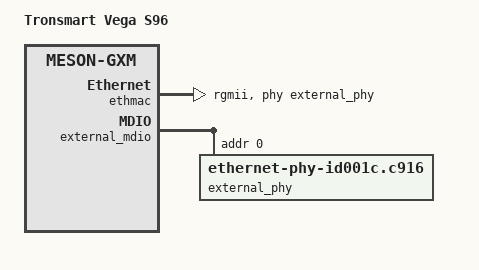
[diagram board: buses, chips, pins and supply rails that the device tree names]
/*
 * Copyright (c) 2017 BayLibre, SAS.
 * Author: Neil Armstrong <narmstrong@baylibre.com>
 * Copyright (c) 2017 Oleg <balbes-150@yandex.ru>
 *
 * SPDX-License-Identifier: (GPL-2.0+ OR MIT)
 */

/dts-v1/;

#include "meson-gxm.dtsi"
#include "meson-gx-p23x-q20x.dtsi"

/ {
	compatible = "tronsmart,vega-s96", "amlogic,s912", "amlogic,meson-gxm";
	model = "Tronsmart Vega S96";

};

&ethmac {
	pinctrl-0 = <&eth_pins>;
	pinctrl-names = "default";

	/* Select external PHY by default */
	phy-handle = <&external_phy>;

	amlogic,tx-delay-ns = <2>;

	/* External PHY is in RGMII */
	phy-mode = "rgmii";
};

&external_mdio {
	external_phy: ethernet-phy@0 {
		compatible = "ethernet-phy-id001c.c916", "ethernet-phy-ieee802.3-c22";
		reg = <0>;
		max-speed = <1000>;
	};
};
